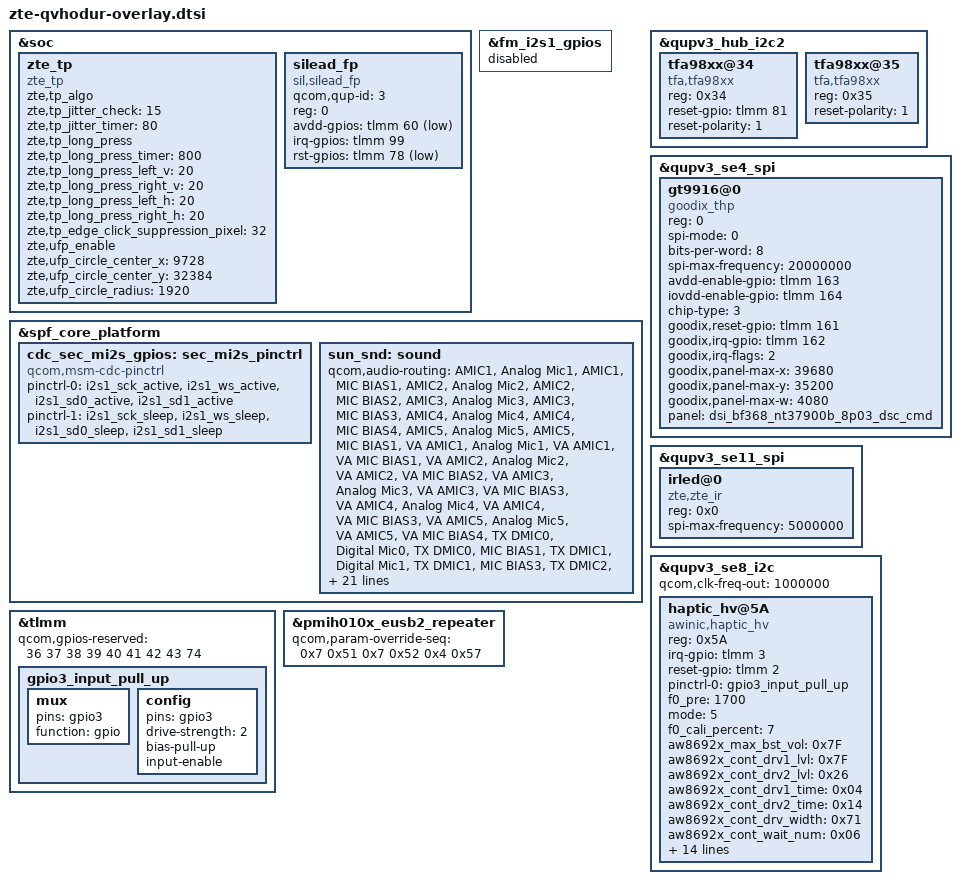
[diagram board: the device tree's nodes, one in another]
/* dtsi for lotus board (Z9900S)*/
#include <dt-bindings/gpio/gpio.h>
#include <dt-bindings/input/input.h>
#include "../zte-fingerprint-sun-goodix.dtsi"


#include "zte-nfc-sn220.dtsi"

&soc {
	zte_tp:zte_tp {
		compatible = "zte_tp";
		zte,tp_algo;
		zte,tp_jitter_check = <15>;
		zte,tp_jitter_timer = <80>;
		zte,tp_long_press;
		zte,tp_long_press_timer = <800>;
		zte,tp_long_press_left_v = <20>;
		zte,tp_long_press_right_v = <20>;
		zte,tp_long_press_left_h = <20>; /*camera */
		zte,tp_long_press_right_h = <20>; /*charger */
		zte,tp_edge_click_suppression_pixel = <32>;
		zte,ufp_enable;
		zte,ufp_circle_center_x = <9728>;
		zte,ufp_circle_center_y = <32384>;
		zte,ufp_circle_radius = <1920>;
	};
};

&fm_i2s1_gpios {
        status = "disabled";
};

&spf_core_platform  {
	cdc_sec_mi2s_gpios: sec_mi2s_pinctrl {
		status = "ok";
		compatible = "qcom,msm-cdc-pinctrl";
		pinctrl-names = "aud_active", "aud_sleep";
		pinctrl-0 = <&i2s1_sck_active &i2s1_ws_active
        	&i2s1_sd0_active &i2s1_sd1_active>;
		pinctrl-1 = <&i2s1_sck_sleep &i2s1_ws_sleep
        	&i2s1_sd0_sleep &i2s1_sd1_sleep>;
	};
 
	sun_snd: sound {
		qcom,audio-routing =
			"AMIC1", "Analog Mic1",
			"AMIC1", "MIC BIAS1",
			"AMIC2", "Analog Mic2",
			"AMIC2", "MIC BIAS2",
			"AMIC3", "Analog Mic3",
			"AMIC3", "MIC BIAS3",
			"AMIC4", "Analog Mic4",
			"AMIC4", "MIC BIAS4",
			"AMIC5", "Analog Mic5",
			"AMIC5", "MIC BIAS1",
			"VA AMIC1", "Analog Mic1",
			"VA AMIC1", "VA MIC BIAS1",
			"VA AMIC2", "Analog Mic2",
			"VA AMIC2", "VA MIC BIAS2",
			"VA AMIC3", "Analog Mic3",
			"VA AMIC3", "VA MIC BIAS3",
			"VA AMIC4", "Analog Mic4",
			"VA AMIC4", "VA MIC BIAS3",
			"VA AMIC5", "Analog Mic5",
			"VA AMIC5", "VA MIC BIAS4",
			"TX DMIC0", "Digital Mic0",
			"TX DMIC0", "MIC BIAS1",
			"TX DMIC1", "Digital Mic1",
			"TX DMIC1", "MIC BIAS3",
			"TX DMIC2", "Digital Mic2",
			"TX DMIC2", "MIC BIAS3",
			"TX DMIC3", "Digital Mic3",
			"TX DMIC3", "MIC BIAS1",
			"IN1_HPHL", "HPHL_OUT",
			"IN2_HPHR", "HPHR_OUT",
			"IN3_EAR", "AUX_OUT",
			"RX_TX DEC0_INP", "TX DEC0 MUX",
			"RX_TX DEC1_INP", "TX DEC1 MUX",
			"RX_TX DEC2_INP", "TX DEC2 MUX",
			"RX_TX DEC3_INP", "TX DEC3 MUX",
			"TX SWR_INPUT", "WCD_TX_OUTPUT",
			"VA SWR_INPUT", "VA_SWR_CLK",
			"VA SWR_INPUT", "WCD_TX_OUTPUT",
			"VA_AIF1 CAP", "VA_SWR_CLK",
			"VA_AIF2 CAP", "VA_SWR_CLK",
			"VA_AIF3 CAP", "VA_SWR_CLK",
			"VA DMIC0", "Digital Mic0",
			"VA DMIC1", "Digital Mic1",
			"VA DMIC2", "Digital Mic2",
			"VA DMIC3", "Digital Mic3",
			"VA DMIC0", "VA MIC BIAS1",
			"VA DMIC1", "VA MIC BIAS3",
			"VA DMIC2", "VA MIC BIAS3",
			"VA DMIC3", "VA MIC BIAS1";
		qcom,msm-mbhc-usbc-audio-supported = <1>;
		qcom,msm-mbhc-hphl-swh = <0>;
		qcom,msm-mbhc-gnd-swh = <0>;
                
                qcom,mi2s-audio-intf = <1>;
                qcom,sec-mi2s-gpios = <&cdc_sec_mi2s_gpios>;
        };
};

&qupv3_hub_i2c2 {
	status = "okay";
	        tfa98xx@34 {
			        compatible = "tfa,tfa98xx";
					reg = <0x34>;
					reset-gpio = <&tlmm 81 0>;
                    //irq-gpio = <&tlmm 128 0x00>;
					reset-polarity=<1>;
			};
		tfa98xx@35 {
			        compatible = "tfa,tfa98xx";
					reg = <0x35>;
					//reset-gpio = <&tlmm 81 0>;
                                        //irq-gpio = <&tlmm 127 0x00>;
				        reset-polarity=<1>;
			};
};

&qupv3_se4_spi {
	status = "ok";

	gt9916@0 {
		compatible = "goodix_thp";
		reg = <0>;
		spi-mode = <0>;
		bits-per-word = <8>;
		spi-max-frequency = <20000000>;
		avdd-enable-gpio = <&tlmm 163 0x0>; /*ts_pwr_en2*/
		iovdd-enable-gpio = <&tlmm 164 0x0>; /*ts_pwr_en3*/
		chip-type = <3>; // 1: gt9897 2: gt9916 3: gt9966 4: gt9615
		goodix,reset-gpio = <&tlmm 161 0x0>;
		goodix,irq-gpio = <&tlmm 162 0x2>;
		goodix,irq-flags = <2>; /* 1:trigger rising, 2:trigger falling;*/
		goodix,panel-max-x = <39680>;
		goodix,panel-max-y = <35200>;
		goodix,panel-max-w = <4080>;
		panel = <&dsi_bf368_nt37900b_8p03_dsc_cmd>;
	};
};

&qupv3_se11_spi {
	status = "ok";
	irled@0 {
		status = "ok";
		compatible = "zte,zte_ir";
		reg = <0x0>;
		spi-max-frequency = <5000000>;
	};
};

/* add zte haptic start */
&qupv3_se8_i2c {
	status = "ok";
	qcom,clk-freq-out = <1000000>;
	haptic_hv@5A {
		compatible = "awinic,haptic_hv";
		reg = <0x5A>;
		irq-gpio = <&tlmm 3 0>;
		reset-gpio = <&tlmm 2 0>;
		pinctrl-names = "irq_active";
		pinctrl-0 = <&gpio3_input_pull_up>;
		f0_pre = < 1700 >;
		mode = /bits/ 8 < 5 >;
		f0_cali_percent = /bits/ 8 < 7 >;
/******************************aw8692x*******************************/
		aw8692x_max_bst_vol = /bits/ 8 < 0x7F >;
		aw8692x_cont_drv1_lvl = /bits/ 8 < 0x7F >;
		aw8692x_cont_drv2_lvl = /bits/ 8 < 0x26 >; /* 0.9Vrms */
		aw8692x_cont_drv1_time = /bits/ 8 < 0x04 >;
		aw8692x_cont_drv2_time = /bits/ 8 < 0x14 >; /* 10 period */
		aw8692x_cont_drv_width = /bits/ 8 < 0x71 >;
		aw8692x_cont_wait_num = /bits/ 8 < 0x06 >;
		aw8692x_cont_brk_time = /bits/ 8 < 0 >;
		aw8692x_cont_track_margin = /bits/ 8 < 0x0C >;
		aw8692x_brk_bst_md = /bits/ 8 < 0 >;
		aw8692x_cont_tset = /bits/ 8 < 0x06 >;
		aw8692x_cont_bemf_set = /bits/ 8 < 0x02 >;
		aw8692x_cont_bst_brk_gain = /bits/ 8 < 0x05 >;
		aw8692x_cont_brk_gain = /bits/ 8 < 0x08 >;
		aw8692x_duration_time = /bits/ 8 < 20 30 60 >;
		aw8692x_d2s_gain = /bits/ 8 < 0x04 >;
		aw8692x_trig_config = /bits/ 8 < 0 0 0 1 0 2 0 0
						 0 0 0 1 0 2 0 0
						 0 0 0 1 0 2 0 0 >;
		aw8692x_bst_vol_default = /bits/ 8 < 0x48 >; /* 8.0Vrms */
		aw8692x_bst_vol_ram = /bits/ 8 < 0x48 >;
		aw8692x_bst_vol_rtp = /bits/ 8 < 0x48 >;
		/* aw8692x_is_enabled_auto_bst; */
		/* aw8692x_is_enabled_one_wire; */
	};
};

&tlmm {
	qcom,gpios-reserved = <36 37 38 39 40 41 42 43 74>;
	gpio3_input_pull_up: gpio3_input_pull_up {
		mux {
			 pins = "gpio3";
			 function = "gpio";
		};

		config {
			pins = "gpio3";
			drive-strength = <2>;
			bias-pull-up;
			input-enable;
		};
	};
};
/* add zte haptic start */

&soc {
	silead_fp {
		status = "ok";
		compatible = "sil,silead_fp";
		qcom,qup-id = <3>;
		reg = <0>;
		avdd-gpios = <&tlmm 60 0x1>;
		irq-gpios = <&tlmm 99 0x2008>;
		rst-gpios = <&tlmm 78 0x1>;
	};
};

&pmih010x_eusb2_repeater {
	qcom,param-override-seq =
		/* <value reg_offset> */
		/* Adjust HS trasmit amplitude */
		<0x7 0x51
		/* TX Output Resistance */
		 0x7 0x52
		/* Tx pre-emphasis tuning */
		 0x4 0x57>;
};
